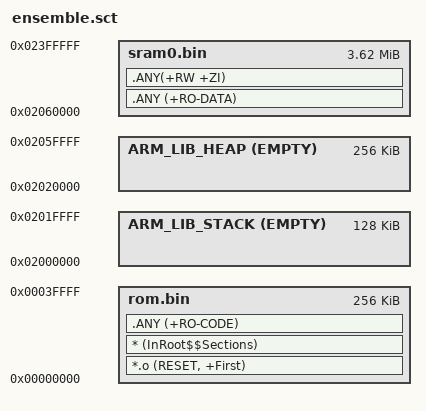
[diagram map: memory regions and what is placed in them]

; *************************************************************
; ***       Scatter-Loading Description File                ***
; *************************************************************

;---------------------------------------------------------
; First load region (ITCM)
;---------------------------------------------------------
LOAD_REGION_0       0x00000000                  0x00040000
{
    ;-----------------------------------------------------
    ; Code region
    ;-----------------------------------------------------
    rom.bin         0x00000000                  0x00040000
    {
        *.o (RESET, +First)
        * (InRoot$$Sections)

        .ANY (+RO-CODE)
    }
}

;---------------------------------------------------------
; Second load region (SRAM0)
;---------------------------------------------------------
LOAD_REGION_1       0x02000000                  0x00400000
{

    ARM_LIB_STACK 0x2000000 EMPTY ALIGN 8      0x00020000
    {}

    ARM_LIB_HEAP  0x2020000 EMPTY ALIGN 8      0x00040000
    {}

    sram0.bin       0x02060000 ALIGN 16         0x003A0000
    {
        ; RO data (incl. unwinding tables for debugging)
        .ANY (+RO-DATA)
        .ANY(+RW +ZI)
    }
}
